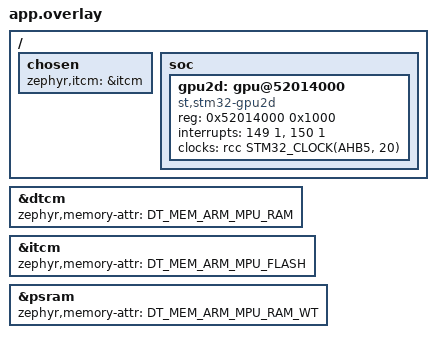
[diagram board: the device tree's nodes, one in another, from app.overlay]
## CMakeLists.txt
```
# SPDX-License-Identifier: Apache-2.0
#
# PSX GPU for the STM32H7S78-DK: the emulator on the i.MX RT1050 sends its GPU
# commands over Ethernet, this board rasterizes them (PSXE/dev/gpu.c, the same
# file the RT1050 build uses) and shows the picture.

cmake_minimum_required(VERSION 3.20.0)

find_package(Zephyr REQUIRED HINTS $ENV{ZEPHYR_BASE})
project(h7s7_psxgpu LANGUAGES C)

set(PSXE_ROOT "${CMAKE_CURRENT_SOURCE_DIR}/..")
set(NEOCHROM_ROOT "${CMAKE_CURRENT_SOURCE_DIR}/../h7s7_neochrom")

# -----------------------------------------------------------------------------
# NemaGFX - the NeoChrom driver library (see h7s7_neochrom/CMakeLists.txt)
# -----------------------------------------------------------------------------
set(NEMAGFX_ROOT "$ENV{NEMAGFX_ROOT}" CACHE PATH "NemaGFX package root")
if(NOT NEMAGFX_ROOT)
  if(DEFINED ZEPHYR_LVGL_MODULE_DIR AND EXISTS "${ZEPHYR_LVGL_MODULE_DIR}/libs/nema_gfx")
    set(NEMAGFX_ROOT "${ZEPHYR_LVGL_MODULE_DIR}/libs/nema_gfx")
  else()
    message(FATAL_ERROR "NemaGFX not found: run 'west update' (lvgl module) or pass -DNEMAGFX_ROOT=<dir>")
  endif()
endif()

if(EXISTS "${NEMAGFX_ROOT}/include/cortex_m55_m7/nema_core.h")
  set(NEMAGFX_INC "${NEMAGFX_ROOT}/include/cortex_m55_m7")
else()
  set(NEMAGFX_INC "${NEMAGFX_ROOT}/include")
endif()

if(CONFIG_FP_HARDABI)
  set(NEMAGFX_LIB "${NEMAGFX_ROOT}/lib/core/cortex_m7/gcc/libnemagfx-float-abi-hard.a")
else()
  set(NEMAGFX_LIB "${NEMAGFX_ROOT}/lib/core/cortex_m7/gcc/libnemagfx.a")
endif()

if(NOT EXISTS "${NEMAGFX_INC}/nema_core.h" OR NOT EXISTS "${NEMAGFX_LIB}")
  message(FATAL_ERROR "Incomplete NemaGFX package in ${NEMAGFX_ROOT}")
endif()
message(STATUS "NemaGFX: ${NEMAGFX_LIB}")

add_library(nemagfx STATIC IMPORTED GLOBAL)
set_target_properties(nemagfx PROPERTIES IMPORTED_LOCATION "${NEMAGFX_LIB}")

# the HAL Ethernet driver's descriptor rings (the same value for the HAL and for us)
zephyr_compile_definitions(ETH_RX_DESC_CNT=64 ETH_TX_DESC_CNT=4)

target_include_directories(app PRIVATE
  src
  src/shim
  "${PSXE_ROOT}/PSXE"
  "${PSXE_ROOT}/PSXE/dev"
  "${PSXE_ROOT}/PSXE/link"
  "${NEOCHROM_ROOT}/src"
  "${NEMAGFX_INC}"
)
target_link_libraries(app PUBLIC nemagfx)

# gpu.h is read by every file here: on its own, without the emulator's ic.h/cpu.h
target_compile_definitions(app PRIVATE PSX_GPU_STANDALONE=1 PSXE_GPU_REMOTE=0 PSX_PROFILE=1)

target_sources(app PRIVATE
  src/main.c
  src/eth_raw.c
  src/present.c
  src/nema_raster.c
  src/shim/psx_shim.c
  "${NEOCHROM_ROOT}/src/nema_hal_zephyr.c"
  "${NEOCHROM_ROOT}/src/font8x8.c"
  "${PSXE_ROOT}/PSXE/dev/gpu.c"
)

# the rasterizer: built as on the RT1050 (-O3, unrolled), on its own
set_source_files_properties("${PSXE_ROOT}/PSXE/dev/gpu.c" PROPERTIES
  COMPILE_OPTIONS "-O3;-funroll-loops;-Wno-unused-function;-Wno-unused-variable;-Wno-sign-compare;-Wno-missing-braces")
```

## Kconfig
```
# SPDX-License-Identifier: Apache-2.0

mainmenu "PSX GPU board"

menu "PSX GPU board"

config PSXGPU_ETH
	bool "Raw Ethernet through the STM32 HAL"
	default y
	select USE_STM32_HAL_ETH
	select NOCACHE_MEMORY
	help
	  The link to the CPU board: raw Ethernet frames through the HAL ETH
	  driver, without the Zephyr network stack (src/eth_raw.c).

# the NemaGFX platform layer shared with the showcase (h7s7_neochrom/src/nema_hal_zephyr.c)
config NEOCHROM_NEMA_POOL_SIZE
	int "NemaGFX graphics memory pool in non-cacheable SRAM [bytes]"
	default 16384
	help
	  The NemaGFX allocator's pool: its ring buffer and little else here.
	  Non-cacheable, so the GPU always sees what the CPU wrote.

config NEOCHROM_GPU2D_ICACHE
	bool "Enable the GPU2D read cache"
	default y
	help
	  The GPU2D's own read cache. Not coherent: the presenter asks for an
	  invalidation (ext-hold) before the GPU reads what the CPU repacked.

endmenu

source "Kconfig.zephyr"
```

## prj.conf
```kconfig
# Display: LTDC, frame buffers owned by the application (zero-copy flip)
CONFIG_DISPLAY=y
CONFIG_STM32_LTDC_RGB565=y
CONFIG_STM32_LTDC_FB_NUM=0
CONFIG_MEMC=y
CONFIG_GPIO=y

# Ethernet: the HAL driver alone, no network stack (see src/eth_raw.c)
CONFIG_NETWORKING=n
CONFIG_PINCTRL=y

# Floating point: NemaGFX is linked in its hard-float flavour
CONFIG_FPU=y
CONFIG_FPU_SHARING=y
CONFIG_FP_HARDABI=y

# CPU <-> GPU / DMA coherency
CONFIG_CACHE_MANAGEMENT=y
CONFIG_NOCACHE_MEMORY=y

# Memory / threads
CONFIG_HEAP_MEM_POOL_SIZE=16384
CONFIG_MAIN_STACK_SIZE=16384
CONFIG_ISR_STACK_SIZE=4096
CONFIG_MAIN_THREAD_PRIORITY=5

# Speed
CONFIG_SPEED_OPTIMIZATIONS=y

# Diagnostics
CONFIG_PRINTK=y
CONFIG_LOG=y
CONFIG_LOG_DEFAULT_LEVEL=3
CONFIG_LOG_BUFFER_SIZE=4096

# Keep the debug port alive while the idle thread sleeps (hot attach, SWD memory dumps)
CONFIG_STM32_ENABLE_DEBUG_SLEEP_STOP=y
```

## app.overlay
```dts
/*
 * NeoChrom GPU2D (Think Silicon NEMA|P): not in the SoC devicetree yet, so the
 * application adds it (as h7s7_neochrom does). RM0477 / stm32h7s7xx.h:
 *   GPU2D_BASE = 0x52014000, IRQs 149 (gpu2d) and 150 (gpu2d_er),
 *   clock: RCC_AHB5ENR bit 20
 */

/ {
	chosen {
		zephyr,itcm = &itcm;
	};

	soc {
		gpu2d: gpu@52014000 {
			compatible = "st,stm32-gpu2d";
			reg = <0x52014000 0x1000>;
			interrupts = <149 1>, <150 1>;
			interrupt-names = "gpu2d", "gpu2d_er";
			clocks = <&rcc STM32_CLOCK(AHB5, 20)>;
			status = "okay";
		};
	};
};

/* an MPU region for the DTCM: the GPU state lives there (psx_gpu_platform.h) */
&dtcm {
	zephyr,memory-attr = <DT_MEM_ARM_MPU_RAM>;
};

/* the innermost rasterizer runs from the ITCM: an executable MPU region (Zephyr's RAM
   attribute is execute-never in an XIP image; the flash one is read-only and executable,
   and the code is copied in at boot, before the MPU is set up) */
&itcm {
	zephyr,memory-attr = <DT_MEM_ARM_MPU_FLASH>;
};

/* the PSRAM (VRAM, frame buffers) write-through: a span written by the rasterizer
   neither fills a cache line first (a 189 cycle read of what it overwrites) nor
   evicts the texture lines it needs next; the write buffer merges the stores */
&psram {
	zephyr,memory-attr = <DT_MEM_ARM_MPU_RAM_WT>;
};
```

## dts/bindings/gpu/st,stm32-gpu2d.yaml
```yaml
# SPDX-License-Identifier: Apache-2.0

description: |
  STM32 NeoChrom graphics accelerator (GPU2D, Think Silicon NEMA|P core).
  The first interrupt signals command-list completion, the second one is the
  "error" line that on AXI-attached instances also carries the GPU cache
  maintenance (external hold) handshakes.

compatible: "st,stm32-gpu2d"

include: base.yaml

properties:
  reg:
    required: true

  interrupts:
    required: true

  interrupt-names:
    required: true

  clocks:
    required: true
```

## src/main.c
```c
/*
 * PSX GPU on the STM32H7S78-DK.
 *
 * The emulator on the i.MX RT1050 sends its GPU commands over Ethernet (see
 * PSXE/link/psxe_link.h); this board keeps the VRAM, rasterizes with the very
 * same gpu.c and shows the picture on its panel.
 *
 *   receive thread   Ethernet frames -> the receive ring (link_ring.h)
 *   main thread      ring -> records -> gpu.c; vertical blank -> present;
 *                    STATUS frames back (flow control), statistics on the UART
 */

#include <string.h>

#include <zephyr/kernel.h>
#include <zephyr/cache.h>
#include <zephyr/device.h>
#include <zephyr/drivers/gpio.h>
#include <zephyr/linker/devicetree_regions.h>
#include <zephyr/sys/printk.h>
#include <zephyr/logging/log.h>

#include "eth_raw.h"
#include "gpu.h"
#include "psx_gpu_platform.h"
#include "link_ring.h"
#include "nema_port.h"
#include "nema_raster.h"
#include "present.h"
#include "psxe_link.h"

LOG_MODULE_REGISTER(main, LOG_LEVEL_INF);

static const uint8_t mac_gpu[6] = PSXE_LINK_MAC_GPU;
static const uint8_t mac_cpu[6] = PSXE_LINK_MAC_CPU;

static uint8_t ring_mem[PSXE_LINK_RING_BYTES]
	__attribute__((section(LINKER_DT_NODE_REGION_NAME(DT_NODELABEL(psram))))) __aligned(64);
static struct link_ring ring;
static K_SEM_DEFINE(ring_sem, 0, 1);

static psx_gpu_t *gpu;

/* link state */
static uint32_t consumed;         /* payload bytes of frames fully processed     */
static uint32_t consumed_told;    /* ... as of the last STATUS                    */
static int64_t status_at;         /* when the last STATUS went out                */
static uint16_t rx_seq;
static bool rx_seq_known;
static bool resync;               /* frames were lost: wait for a command boundary */
static uint32_t errors;
static uint32_t lost_frames, resyncs, ring_full, bad_frames;
static uint32_t dropped_bytes; /* frames the ring had no room for: never stored, so consumed at once */
static uint32_t boot_id;
static uint32_t frames_in, words_gp0, gp1_words, vblanks;
static uint32_t pictures;         /* finished pictures from the CPU board (the hybrid) */
static uint32_t busy_cyc;         /* cycles spent processing frames since the last report */
static int64_t last_frame_at;

#if DT_NODE_EXISTS(DT_ALIAS(led0))
static const struct gpio_dt_spec led = GPIO_DT_SPEC_GET(DT_ALIAS(led0), gpios);
#endif

/* ---- receive thread ---------------------------------------------------------- */

static void rx_sink(const uint8_t *frame, size_t len)
{
	if (len < PSXE_LINK_ETH_HDR + PSXE_LINK_HDR) {
		return;
	}
	if (frame[12] != (PSXE_LINK_ETHERTYPE >> 8) || frame[13] != (PSXE_LINK_ETHERTYPE & 0xffu)) {
		return; /* not ours */
	}
	if (!link_ring_put(&ring, frame + PSXE_LINK_ETH_HDR, (uint32_t)(len - PSXE_LINK_ETH_HDR))) {
		ring_full++;
		errors++;
		dropped_bytes += (uint32_t)(len - PSXE_LINK_ETH_HDR);
		return;
	}
	k_sem_give(&ring_sem);
}

static void rx_thread(void *a, void *b, void *c)
{
	ARG_UNUSED(a);
	ARG_UNUSED(b);
	ARG_UNUSED(c);
	while (1) {
		(void)eth_raw_receive(rx_sink, K_MSEC(100));
	}
}

K_THREAD_DEFINE(rx_tid, 4096, rx_thread, NULL, NULL, NULL, K_PRIO_PREEMPT(1), 0, 0);

/* ---- sending ---------------------------------------------------------------- */

/* the payload 4 byte aligned: the Ethernet header is 14 bytes */
static uint8_t tx_frame_mem[2 + PSXE_LINK_FRAME_MAX] __aligned(4);
#define tx_frame (tx_frame_mem + 2)
static uint16_t tx_seq;

static uint32_t *tx_begin(void)
{
	memcpy(tx_frame, mac_cpu, 6);
	memcpy(tx_frame + 6, mac_gpu, 6);
	tx_frame[12] = PSXE_LINK_ETHERTYPE >> 8;
	tx_frame[13] = PSXE_LINK_ETHERTYPE & 0xffu;
	tx_frame[14] = PSXE_LINK_VERSION;
	tx_frame[15] = 0;
	tx_frame[16] = (uint8_t)tx_seq;
	tx_frame[17] = (uint8_t)(tx_seq >> 8);
	tx_seq++;
	return (uint32_t *)(tx_frame + PSXE_LINK_ETH_HDR + PSXE_LINK_HDR);
}

static void tx_end(uint32_t *end)
{
	size_t len = (size_t)((uint8_t *)end - tx_frame);

	if (len < 60) {
		memset(tx_frame + len, 0, 60 - len);
		len = 60;
	}
	(void)eth_raw_send(tx_frame, len);
}

static void send_status(void)
{
	struct present_stats ps;
	uint32_t *w = tx_begin();

	present_get_stats(&ps);
	w[0] = PSXE_REC_HDR(PSXE_REC_STATUS, 0, PSXE_STATUS_WORDS);
	w[1 + PSXE_STATUS_CONSUMED] = consumed + dropped_bytes;
	w[1 + PSXE_STATUS_FLAGS] = PSXE_STATUS_FLAG_READY | (resync ? PSXE_STATUS_FLAG_RESYNC : 0u);
	w[1 + PSXE_STATUS_RING] = PSXE_LINK_RING_BYTES;
	w[1 + PSXE_STATUS_PRESENTED] = ps.frames;
	w[1 + PSXE_STATUS_ERRORS] = errors;
	w[1 + PSXE_STATUS_BOOT] = boot_id;
	w[1 + PSXE_STATUS_BUSY] = 0; /* not measured here: sent as zero rather than as whatever the buffer held */
	tx_end(w + 1 + PSXE_STATUS_WORDS);
	consumed_told = consumed;
	status_at = k_uptime_get();
}

/* the words a VRAM -> CPU transfer returns, as GPUREAD would give them */
static void send_vram_read(void)
{
	while (gpu->c0_tsiz > 0) {
		uint32_t n = (uint32_t)(gpu->c0_tsiz + 1) / 2u;

		if (n > PSXE_LINK_PAYLOAD_WORDS - 1u) {
			n = PSXE_LINK_PAYLOAD_WORDS - 1u;
		}
		uint32_t *w = tx_begin();

		w[0] = PSXE_REC_HDR(PSXE_REC_VRAM, 0, n);
		for (uint32_t i = 0; i < n; i++) {
			w[1 + i] = psx_gpu_read32(gpu, 0);
		}
		tx_end(w + 1 + n);
	}
}

/* ---- the command stream ------------------------------------------------------- */

static void gpu_reset(void)
{
	psx_gpu_init(gpu, NULL);
	resync = false;
	LOG_INF("GPU reset by the CPU board");
}

static void feed_gp0(const uint32_t *w, uint32_t n)
{
	while (n) {
		if (gpu->state == GPU_STATE_RECV_DATA) {
			/* whole rows of an upload straight into VRAM */
			uint32_t done = psx_gpu_write_bulk(gpu, w, n);

			if (done) {
				w += done;
				n -= done;
				continue;
			}
		}
		psx_gpu_write32(gpu, 0, *w++);
		n--;
		if (gpu->c0_tsiz > 0) {
			send_vram_read();
		}
	}
}

/* the last few megabytes of what came over the link, for a debugger to read:
   g_cap_pos is where the next frame goes; each frame is its length in bytes
   (one word, then the payload padded to words), capturing stops when it is full */
#define CAP_BYTES (8u * 1024u * 1024u)
uint8_t g_cap[CAP_BYTES] __attribute__((section(LINKER_DT_NODE_REGION_NAME(DT_NODELABEL(psram))))) __aligned(64);
volatile uint32_t g_cap_pos;
volatile uint32_t g_cap_wraps;
volatile uint32_t g_cap_on = 1;

/* a debugger writes a capture into g_cap and sets this to 1: the stream is fed
   from there instead of the link, up to g_replay_vblanks vertical blanks (0 =
   all of it), and then everything stops at 2 so that VRAM can be read */
volatile uint32_t g_replay;
volatile uint32_t g_replay_vblanks;

static void capture(const uint8_t *p, uint32_t len)
{
	const uint32_t need = 4u + ((len + 3u) & ~3u);

	if (!g_cap_on) {
		return;
	}
	if (g_cap_pos + need + 4u > CAP_BYTES) {
		*(uint32_t *)&g_cap[g_cap_pos] = 0xffffffffu; /* the end marker */
		g_cap_on = 0; /* the first CAP_BYTES since boot: the VRAM restore, then the stream */
		g_cap_wraps++;
		return;
	}
	*(uint32_t *)&g_cap[g_cap_pos] = len;
	memcpy(&g_cap[g_cap_pos + 4u], p, len);
	g_cap_pos += need;
}

static void process_frame(const uint8_t *p, uint32_t len)
{
	if (!g_replay) {
		capture(p, len);
	}
	if (PSXE_LINK_HDR_VERSION(p) != PSXE_LINK_VERSION) {
		bad_frames++;
		errors++;
		return;
	}
	uint16_t seq = PSXE_LINK_HDR_SEQ(p);

	if (rx_seq_known && seq != rx_seq) {
		lost_frames += (uint16_t)(seq - rx_seq);
		errors++;
		resync = true;
	}
	rx_seq = (uint16_t)(seq + 1);
	rx_seq_known = true;
	frames_in++;

	const uint32_t *w = (const uint32_t *)(p + PSXE_LINK_HDR);
	uint32_t words = (len - PSXE_LINK_HDR) / 4u;

	while (words >= 1u) {
		const uint32_t h = *w++;
		const uint32_t n = PSXE_REC_LEN(h);

		words--;
		if (n > words) {
			bad_frames++;
			errors++;
			break;
		}
		switch (PSXE_REC_TYPE(h)) {
		case PSXE_REC_GP0:
			if (resync) {
				if (!(PSXE_REC_FLAGS(h) & PSXE_REC_GP0_BOUNDARY)) {
					break; /* mid-command: wait for a boundary */
				}
				gpu->state = GPU_STATE_RECV_CMD;
				resync = false;
				resyncs++;
			}
			feed_gp0(w, n);
			words_gp0 += n;
			break;
		case PSXE_REC_GP1:
			if (n >= 1u) {
				psx_gpu_write32(gpu, 4, w[0]);
				gp1_words++;
			}
			break;
		case PSXE_REC_FRAME:
			if (n >= PSXE_FRAME_WORDS) {
				const uint32_t pw = w[0] & 0xffffu;
				const uint32_t ph = w[0] >> 16;
				const uint32_t row = w[1] & 0xffffu;
				const uint32_t rows = w[1] >> 16;
				const uint32_t flags = w[2];
				const uint32_t mode = w[3];
				const uint32_t row_bytes = (flags & PSXE_FRAME_24BPP) ? (pw * 3u) : (pw * 2u);
				const uint32_t row_words = (row_bytes + 3u) >> 2;
				const uint32_t *px = w + PSXE_FRAME_WORDS;

				if (pw && (pw <= PSX_GPU_FB_WIDTH) && ((row + rows) <= PSX_GPU_FB_HEIGHT) &&
				    (PSXE_FRAME_WORDS + rows * row_words <= n)) {
					/* a whole picture makes good whatever a lost frame spoiled */
					if (flags & PSXE_FRAME_WHOLE) {
						resync = false;
					}
					present_rows(px, pw, row, rows, row_words * 4u, flags);

					if (flags & PSXE_FRAME_LAST) {
						present_show(pw, ph, flags, mode);
						pictures++;
					}
				} else {
					bad_frames++;
					errors++;
				}
			}
			break;

		case PSXE_REC_VBLANK:
			if (n >= 1u) {
				psx_gpu_set_field(gpu, PSXE_VBLANK_FIELD(w[0]));
				vblanks++;
				present_vblank(gpu);
			}
			break;
		case PSXE_REC_RESET:
			gpu_reset();
			break;
		default:
			break;
		}
		w += n;
		words -= n;
	}
	consumed += len;
}

static void replay(void)
{
	uint32_t pos = 0;
	const uint32_t vb0 = vblanks;

	g_cap_on = 0;
	rx_seq_known = false;
	LOG_INF("replaying the capture");
	while (pos + 4u <= CAP_BYTES) {
		const uint32_t len = *(const uint32_t *)&g_cap[pos];

		if ((len == 0xffffffffu) || (len == 0u) || (len > PSXE_LINK_FRAME_MAX)) {
			break;
		}
		process_frame(&g_cap[pos + 4u], len);
		pos += 4u + ((len + 3u) & ~3u);
		if (g_replay_vblanks && ((vblanks - vb0) >= g_replay_vblanks)) {
			break;
		}
	}
	psx_raster_sync();
	sys_cache_data_invd_range(gpu->vram, PSX_GPU_VRAM_SIZE);
	LOG_INF("replay done: %u bytes, %u vblanks", pos, vblanks - vb0);
	g_replay = 2;
	while (g_replay == 2) {
		k_msleep(10);
	}
}

/* ---- main --------------------------------------------------------------------- */

int main(void)
{
	printk("\n*** PSX GPU board - %s ***\n", CONFIG_BOARD_TARGET);

#if DT_NODE_EXISTS(DT_ALIAS(led0))
	if (gpio_is_ready_dt(&led)) {
		gpio_pin_configure_dt(&led, GPIO_OUTPUT_INACTIVE);
	}
#endif

	link_ring_init(&ring, ring_mem, sizeof(ring_mem));
	boot_id = k_cycle_get_32() | 1u;

	if (present_init() != 0) {
		LOG_ERR("display init failed");
		return 0;
	}
	psxgpu_prof_init();
	gpu = psx_gpu_create();
	psx_gpu_init(gpu, NULL);
	psxgpu_mem_bench();
	present_bench(gpu);
	psx_raster_selftest(gpu);
	psx_raster_tritest(gpu);
	if (gpu->vram == NULL) {
		LOG_ERR("no VRAM");
		return 0;
	}
	present_text("PSX GPU", "waiting for the CPU board (Ethernet)");

	if (eth_raw_init(mac_gpu) != 0) {
		present_text("PSX GPU", "Ethernet init failed");
		return 0;
	}

	int64_t t_log = k_uptime_get();
	int64_t t_link = 0;
	bool shown_waiting = true;
	bool was_up = false;

	while (1) {
		int64_t now = k_uptime_get();

		/* the PHY, every 200 ms */
		if (now - t_link >= 200) {
			t_link = now;
			bool up = eth_raw_link_poll();

			if (up != was_up) {
				was_up = up;
				if (up) {
					send_status();
				}
			}
		}

		if (g_replay == 1) {
			replay();
		}

		/* everything the ring holds */
		uint32_t len;
		const uint8_t *p;
		int n = 0;

		while ((p = link_ring_peek(&ring, &len)) != NULL) {
			const uint32_t t0 = k_cycle_get_32();

			process_frame(p, len);
			busy_cyc += k_cycle_get_32() - t0;
			link_ring_drop(&ring, len);
			last_frame_at = now;
			shown_waiting = false;
			if (++n >= 64) {
				break; /* let the status go out */
			}
		}

		/* flow control: what was consumed, promptly; and a heartbeat */
		if (eth_raw_link_up()) {
			if ((consumed - consumed_told) >= 16u * 1024u ||
			    ((consumed != consumed_told) && (now - status_at >= 2)) ||
			    (now - status_at >= 250)) {
				send_status();
			}
		}

		if (n == 0) {
			(void)k_sem_take(&ring_sem, K_MSEC(2));
		}

		now = k_uptime_get();
		if (!shown_waiting && now - last_frame_at > 3000) {
			present_text("PSX GPU", eth_raw_link_up() ? "no commands from the CPU board"
							       : "no Ethernet link");
			shown_waiting = true;
		}

		if (now - t_log >= 5000) {
			struct eth_raw_stats es;
			struct present_stats ps;
			struct nema_port_stats ns;
			struct psx_raster_stats rs;

			const uint32_t window_ms = (uint32_t)(now - t_log);
			const uint32_t busy_ms = k_cyc_to_ms_floor32(busy_cyc);

			t_log = now;
			eth_raw_get_stats(&es);
			present_get_stats(&ps);
			nema_port_get_stats(&ns);
			psx_raster_get_stats(&rs);
			printk("link %s: rx %u frames %u KB (drop %u nodesc %u) tx %u (err %u) irq %u | "
			       "gp0 %u words, gp1 %u, vblank %u, lost %u, resync %u, ring full %u, "
			       "bad %u, ring %u/%u KB | pictures %u presented %u (skipped %u) %ux%u mode %03x "
			       "repack %u us gpu %u us | busy %u%% (present %u%%) | gpu2d irq %u err %u timeouts %u\n",
			       eth_raw_link_up() ? "up" : "down", es.rx_frames, es.rx_bytes / 1024u,
			       es.rx_dropped, es.rx_no_desc, es.tx_frames, es.tx_errors, es.irqs, words_gp0, gp1_words,
			       vblanks, lost_frames, resyncs, ring_full, bad_frames,
			       ring.high_water / 1024u, ring.size / 1024u, pictures, ps.frames, ps.skipped,
			       ps.src_w, ps.src_h, ps.mode, ps.repack_us, ps.gpu_us,
			       (busy_ms * 100u) / (window_ms ? window_ms : 1u),
			       (ps.cpu_us_acc / 10u) / (window_ms ? window_ms : 1u), ns.cl_irqs, ns.err_irqs,
			       ns.timeouts);
			printk("raster: %u prims (%u flat, %u gouraud, %u textured, %u rects, %u lines) | "
			       "%u binds (%u 15bpp), %u palettes | %u flushes | cpu %u ms (bind %u ms), gpu %u ms, %u hangs\n",
			       rs.prims, rs.flat, rs.gouraud, rs.textured, rs.rects, rs.lines, rs.tex_binds,
			       rs.tex15, rs.palettes, rs.flushes, k_cyc_to_ms_floor32(rs.cpu_cyc),
			       k_cyc_to_ms_floor32(rs.bind_cyc), k_cyc_to_ms_floor32(rs.gpu_cyc), rs.hangs);
			psx_raster_reset_stats();
			ring.high_water = 0;
			busy_cyc = 0;
			present_stats_reset();
			psxgpu_prof_report();
#if DT_NODE_EXISTS(DT_ALIAS(led0))
			if (gpio_is_ready_dt(&led)) {
				gpio_pin_toggle_dt(&led);
			}
#endif
		}
	}
	return 0;
}
```

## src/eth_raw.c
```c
/*
 * Raw Ethernet through the STM32 HAL ETH driver (the same HAL the Zephyr
 * Ethernet driver uses underneath), on the LAN8742 PHY of the STM32H7S78-DK.
 *
 * Receive: the HAL hands the DMA a buffer through HAL_ETH_RxAllocateCallback
 * and links what it filled through HAL_ETH_RxLinkCallback; HAL_ETH_ReadData
 * returns the chain of one frame. A frame fits one buffer (the buffers are
 * larger than a frame), so a chain is one buffer long here.
 * Transmit: one frame at a time, waited for - the GPU board sends little.
 *
 * Descriptors and buffers are in non-cacheable SRAM (CONFIG_NOCACHE_MEMORY),
 * so no cache maintenance is needed on either side.
 */

#include <stdio.h>
#include <string.h>

#include <zephyr/kernel.h>
#include <zephyr/device.h>
#include <zephyr/devicetree.h>
#include <zephyr/irq.h>
#include <zephyr/drivers/clock_control.h>
#include <zephyr/drivers/clock_control/stm32_clock_control.h>
#include <zephyr/drivers/pinctrl.h>
#include <zephyr/linker/section_tags.h>
#include <zephyr/linker/devicetree_regions.h>
#include <zephyr/cache.h>
#include <zephyr/logging/log.h>
#include <soc.h>

#include <stm32h7rsxx_hal.h>

#include "eth_raw.h"

LOG_MODULE_REGISTER(eth_raw, LOG_LEVEL_INF);

#define ETH_NODE DT_NODELABEL(mac)
#define MDIO_NODE DT_NODELABEL(mdio)
BUILD_ASSERT(DT_NODE_HAS_STATUS_OKAY(ETH_NODE), "the board's Ethernet node is off");
BUILD_ASSERT(DT_NODE_HAS_STATUS_OKAY(MDIO_NODE), "the board's MDIO node is off");

/* the RMII pins are the MAC's; MDC (PC1, behind JP6) and MDIO (PA2) are the MDIO node's */
PINCTRL_DT_DEFINE(ETH_NODE);
PINCTRL_DT_DEFINE(MDIO_NODE);

#define PHY_ADDR 0U  /* LAN8742A on the DK: address 0 (see the board devicetree) */

/* IEEE 802.3 registers, and the LAN8742's speed/duplex status */
#define PHY_BMCR 0U
#define PHY_BMSR 1U
#define PHY_SCSR 31U
#define PHY_BMCR_RESET BIT(15)
#define PHY_BMCR_AUTONEG BIT(12)
#define PHY_BMCR_RESTART_AN BIT(9)
#define PHY_BMSR_AN_DONE BIT(5)
#define PHY_BMSR_LINK BIT(2)
#define PHY_SCSR_SPEED_MASK (7U << 2)
#define PHY_SCSR_100M BIT(3)
#define PHY_SCSR_FULL BIT(4)

#define RX_BUF_SIZE 1536U  /* > 1514 + CRC, a multiple of 32 */
#define RX_BUFS (ETH_RX_DESC_CNT * 2)
#define TX_BUF_SIZE 1536U

static ETH_HandleTypeDef heth;
static ETH_DMADescTypeDef rx_desc[ETH_RX_DESC_CNT] __nocache __aligned(32);
static ETH_DMADescTypeDef tx_desc[ETH_TX_DESC_CNT] __nocache __aligned(32);
/* the receive buffers are in the PSRAM (there are many, so that a burst at line
   rate never runs the DMA out of them); the CPU only ever reads them, after an
   invalidate, so the cache never holds anything the DMA could be overwritten by */
static uint8_t rx_buf[RX_BUFS][RX_BUF_SIZE] __attribute__((section(LINKER_DT_NODE_REGION_NAME(DT_NODELABEL(psram)))))
	__aligned(32);
static uint8_t tx_buf[TX_BUF_SIZE] __nocache __aligned(32);
static uint32_t rx_no_desc; /* the DMA had no descriptor for a frame (receive buffer unavailable) */

/* what the HAL chains: one per receive buffer */
struct rx_chunk {
	struct rx_chunk *next;
	uint16_t len;
	bool used;
};

static struct rx_chunk rx_chunk[RX_BUFS];
static uint8_t mac_addr[6];
static bool link_up;
static bool started;
static K_SEM_DEFINE(rx_sem, 0, 1);
static K_SEM_DEFINE(tx_sem, 0, 1);
static K_MUTEX_DEFINE(tx_mtx);
static struct eth_raw_stats stats;

/* ---- HAL callbacks ------------------------------------------------------- */

void HAL_ETH_RxAllocateCallback(uint8_t **buff)
{
	for (int i = 0; i < RX_BUFS; i++) {
		if (!rx_chunk[i].used) {
			rx_chunk[i].used = true;
			rx_chunk[i].next = NULL;
			rx_chunk[i].len = 0;
			*buff = rx_buf[i];
			return;
		}
	}
	stats.rx_dropped++;
	*buff = NULL;
}

void HAL_ETH_RxLinkCallback(void **pStart, void **pEnd, uint8_t *buff, uint16_t Length)
{
	int i = (int)((buff - &rx_buf[0][0]) / RX_BUF_SIZE);
	struct rx_chunk *c = &rx_chunk[i];

	c->len = Length;
	c->next = NULL;
	if (*pStart == NULL) {
		*pStart = c;
	} else {
		((struct rx_chunk *)*pEnd)->next = c;
	}
	*pEnd = c;
}

void HAL_ETH_TxFreeCallback(uint32_t *buff)
{
	ARG_UNUSED(buff);
}

void HAL_ETH_RxCpltCallback(ETH_HandleTypeDef *h)
{
	ARG_UNUSED(h);
	k_sem_give(&rx_sem);
}

void HAL_ETH_TxCpltCallback(ETH_HandleTypeDef *h)
{
	ARG_UNUSED(h);
	k_sem_give(&tx_sem);
}

void HAL_ETH_ErrorCallback(ETH_HandleTypeDef *h)
{
	if ((HAL_ETH_GetDMAError(h) & ETH_DMA_RX_BUFFER_UNAVAILABLE_FLAG) != 0U) {
		rx_no_desc++;
	}
	stats.tx_errors++;
	/* a receive buffer shortage stops the DMA: it goes on once buffers are back */
	k_sem_give(&rx_sem);
}

static void eth_isr(const void *arg)
{
	ARG_UNUSED(arg);
	stats.irqs++;
	HAL_ETH_IRQHandler(&heth);
}

/* ---- PHY ------------------------------------------------------------------ */

static int phy_read(uint32_t reg, uint32_t *val)
{
	return HAL_ETH_ReadPHYRegister(&heth, PHY_ADDR, reg, val) == HAL_OK ? 0 : -EIO;
}

static int phy_write(uint32_t reg, uint32_t val)
{
	return HAL_ETH_WritePHYRegister(&heth, PHY_ADDR, reg, val) == HAL_OK ? 0 : -EIO;
}

/* the PHY's registers on the console: identity, negotiation, the LAN8742's speed word */
static void phy_dump(const char *when)
{
	static const uint32_t regs[] = {0, 1, 2, 3, 4, 5, 17, 18, 27, 31};
	char line[160];
	size_t n = 0;

	for (size_t i = 0; i < ARRAY_SIZE(regs); i++) {
		uint32_t v = 0;

		if (phy_read(regs[i], &v)) {
			n += snprintf(line + n, sizeof(line) - n, " r%u=????", (unsigned)regs[i]);
		} else {
			n += snprintf(line + n, sizeof(line) - n, " r%u=%04x", (unsigned)regs[i], (unsigned)v);
		}
		if (n >= sizeof(line) - 12) {
			break;
		}
	}
	LOG_INF("PHY %s:%s", when, line);
}

static int phy_init(void)
{
	uint32_t v;

	if (phy_write(PHY_BMCR, PHY_BMCR_RESET)) {
		return -EIO;
	}
	for (int i = 0; i < 100; i++) {
		k_msleep(5);
		if (phy_read(PHY_BMCR, &v) == 0 && (v & PHY_BMCR_RESET) == 0U) {
			break;
		}
	}
	if (phy_read(PHY_BMCR, &v) || (v & PHY_BMCR_RESET)) {
		LOG_ERR("PHY does not answer (BMCR %08x) - is JP6 in the PC1 position?", v);
		phy_dump("dead");
		return -EIO;
	}
	int ret = phy_write(PHY_BMCR, PHY_BMCR_AUTONEG | PHY_BMCR_RESTART_AN);

	phy_dump("after init");
	return ret;
}

/* the link came up: the MAC takes the negotiated speed and duplex, and runs */
static int mac_start(void)
{
	ETH_MACConfigTypeDef mac;
	uint32_t scsr = 0;

	(void)phy_read(PHY_SCSR, &scsr);
	if (HAL_ETH_GetMACConfig(&heth, &mac) != HAL_OK) {
		return -EIO;
	}
	mac.Speed = (scsr & PHY_SCSR_100M) ? ETH_SPEED_100M : ETH_SPEED_10M;
	mac.DuplexMode = (scsr & PHY_SCSR_FULL) ? ETH_FULLDUPLEX_MODE : ETH_HALFDUPLEX_MODE;
	if (HAL_ETH_SetMACConfig(&heth, &mac) != HAL_OK) {
		return -EIO;
	}
	if (HAL_ETH_Start_IT(&heth) != HAL_OK) {
		LOG_ERR("HAL_ETH_Start_IT failed");
		return -EIO;
	}
	started = true;
	LOG_INF("link up: %s %s duplex", (scsr & PHY_SCSR_100M) ? "100 Mbit" : "10 Mbit",
		(scsr & PHY_SCSR_FULL) ? "full" : "half");
	return 0;
}

static void mac_stop(void)
{
	if (started) {
		(void)HAL_ETH_Stop_IT(&heth);
		started = false;
	}
	LOG_INF("link down");
}

bool eth_raw_link_poll(void)
{
	uint32_t bmsr = 0;
	static uint32_t polls;

	if (phy_read(PHY_BMSR, &bmsr)) {
		if ((++polls % 50) == 0) {
			LOG_WRN("PHY MDIO read fails - is JP6 in the PC1 position?");
		}
		return link_up;
	}
	if (!(bmsr & PHY_BMSR_LINK) && ((++polls % 50) == 0)) {
		phy_dump("no link");
	}
	/* the link bit latches low: read twice to see the current state. A low
	   first read while the link is up here means it went down and came back
	   between two polls - renegotiated, possibly to another duplex (a partner
	   that was not negotiating yet gives half duplex): the MAC has to take the
	   new result, or every frame collides with a full duplex partner */
	bool flapped = false;

	if ((bmsr & PHY_BMSR_LINK) == 0U) {
		flapped = link_up;
		(void)phy_read(PHY_BMSR, &bmsr);
	}
	bool up = (bmsr & PHY_BMSR_LINK) != 0U && (bmsr & PHY_BMSR_AN_DONE) != 0U;

	if (up && link_up && flapped) {
		mac_stop();
		link_up = false;
	}
	if (up && !link_up) {
		if (mac_start() == 0) {
			link_up = true;
		}
	} else if (!up && link_up) {
		mac_stop();
		link_up = false;
	}
	return link_up;
}

bool eth_raw_link_up(void)
{
	return link_up;
}

/* ---- init ----------------------------------------------------------------- */

int eth_raw_init(const uint8_t mac[6])
{
	static const struct stm32_pclken pclken[] = STM32_DT_CLOCKS(ETH_NODE);
	const struct device *clk = DEVICE_DT_GET(STM32_CLOCK_CONTROL_NODE);
	int ret;

	memcpy(mac_addr, mac, 6);

	if (!device_is_ready(clk)) {
		return -ENODEV;
	}
	for (size_t i = 0; i < ARRAY_SIZE(pclken); i++) {
		ret = clock_control_on(clk, (clock_control_subsys_t)&pclken[i]);
		if (ret) {
			LOG_ERR("clock %u: %d", (unsigned)i, ret);
			return ret;
		}
	}
	ret = pinctrl_apply_state(PINCTRL_DT_DEV_CONFIG_GET(ETH_NODE), PINCTRL_STATE_DEFAULT);
	if (ret) {
		LOG_ERR("pinctrl (mac): %d", ret);
		return ret;
	}
	ret = pinctrl_apply_state(PINCTRL_DT_DEV_CONFIG_GET(MDIO_NODE), PINCTRL_STATE_DEFAULT);
	if (ret) {
		LOG_ERR("pinctrl (mdio): %d", ret);
		return ret;
	}

	heth.Instance = ETH;
	heth.Init.MACAddr = mac_addr;
	heth.Init.MediaInterface = HAL_ETH_RMII_MODE;
	heth.Init.TxDesc = tx_desc;
	heth.Init.RxDesc = rx_desc;
	heth.Init.RxBuffLen = RX_BUF_SIZE;

	if (HAL_ETH_Init(&heth) != HAL_OK) {
		LOG_ERR("HAL_ETH_Init failed (%08x)", HAL_ETH_GetError(&heth));
		return -EIO;
	}

	IRQ_CONNECT(DT_IRQN(ETH_NODE), DT_IRQ(ETH_NODE, priority), eth_isr, NULL, 0);
	irq_enable(DT_IRQN(ETH_NODE));

	ret = phy_init();
	if (ret) {
		return ret;
	}
	LOG_INF("Ethernet ready, MAC %02x:%02x:%02x:%02x:%02x:%02x, waiting for the link", mac[0],
		mac[1], mac[2], mac[3], mac[4], mac[5]);
	return 0;
}

/* ---- data ----------------------------------------------------------------- */

int eth_raw_receive(eth_raw_sink_t sink, k_timeout_t timeout)
{
	void *chain = NULL;
	int n = 0;

	if (!started) {
		k_sleep(timeout);
		return 0;
	}
	(void)k_sem_take(&rx_sem, timeout);

	while (HAL_ETH_ReadData(&heth, &chain) == HAL_OK) {
		struct rx_chunk *c = chain;
		size_t len = 0;

		for (struct rx_chunk *p = c; p != NULL; p = p->next) {
			len += p->len;
		}
		if (c != NULL && c->next == NULL) {
			sys_cache_data_invd_range((void *)rx_buf[c - rx_chunk], c->len);
			sink(rx_buf[c - rx_chunk], c->len);
		} else if (c != NULL) {
			/* longer than a buffer: cannot be one of ours */
			stats.rx_dropped++;
		}
		for (struct rx_chunk *p = c; p != NULL;) {
			struct rx_chunk *nx = p->next;

			p->used = false;
			p = nx;
		}
		stats.rx_frames++;
		stats.rx_bytes += len;
		n++;
		chain = NULL;
	}
	return n;
}

int eth_raw_send(const void *frame, size_t len)
{
	ETH_BufferTypeDef buf = {
		.buffer = tx_buf,
		.len = len,
		.next = NULL,
	};
	ETH_TxPacketConfigTypeDef cfg = {
		.Attributes = ETH_TX_PACKETS_FEATURES_CRCPAD,
		.CRCPadCtrl = ETH_CRC_PAD_INSERT,
		.ChecksumCtrl = ETH_CHECKSUM_DISABLE,
		.Length = len,
		.TxBuffer = &buf,
		.pData = NULL,
	};
	int ret = 0;

	if (!started || len > TX_BUF_SIZE) {
		return -ENETDOWN;
	}
	k_mutex_lock(&tx_mtx, K_FOREVER);
	memcpy(tx_buf, frame, len);
	k_sem_reset(&tx_sem);
	if (HAL_ETH_Transmit_IT(&heth, &cfg) != HAL_OK) {
		stats.tx_errors++;
		ret = -EIO;
	} else if (k_sem_take(&tx_sem, K_MSEC(20)) != 0) {
		stats.tx_errors++;
		ret = -ETIMEDOUT;
	} else {
		stats.tx_frames++;
	}
	(void)HAL_ETH_ReleaseTxPacket(&heth);
	k_mutex_unlock(&tx_mtx);
	return ret;
}

void eth_raw_get_stats(struct eth_raw_stats *st)
{
	stats.rx_no_desc = rx_no_desc;
	*st = stats;
}
```

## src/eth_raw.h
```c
/*
 * Raw Ethernet on the STM32H7S78-DK: the HAL ETH driver and the LAN8742 PHY,
 * frames in and out, nothing above them. The link protocol does not need IP,
 * and the Zephyr network stack would copy every frame twice and schedule it
 * through two threads on the way.
 */
#ifndef ETH_RAW_H_
#define ETH_RAW_H_

#include <stdbool.h>
#include <stddef.h>
#include <stdint.h>

#include <zephyr/kernel.h>

/* a received frame, handed to the sink whole (Ethernet header included) */
typedef void (*eth_raw_sink_t)(const uint8_t *frame, size_t len);

int eth_raw_init(const uint8_t mac[6]);

/* PHY link state; polls the PHY, so call it every few hundred milliseconds */
bool eth_raw_link_poll(void);
bool eth_raw_link_up(void);

/* blocks until the frames the DMA has received are handed to the sink, or
   until the timeout; returns the number of frames */
int eth_raw_receive(eth_raw_sink_t sink, k_timeout_t timeout);

/* copies the frame into a DMA buffer and sends it; blocks until the DMA has
   taken it over */
int eth_raw_send(const void *frame, size_t len);

struct eth_raw_stats {
	uint32_t rx_frames;
	uint32_t rx_bytes;
	uint32_t rx_dropped;
	uint32_t rx_no_desc; /* frames the DMA had no descriptor for */   /* no free DMA buffer */
	uint32_t tx_frames;
	uint32_t tx_errors;
	uint32_t irqs;
};

void eth_raw_get_stats(struct eth_raw_stats *st);

#endif /* ETH_RAW_H_ */
```

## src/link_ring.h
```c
/*
 * A ring of received frames: one producer (the Ethernet receive thread), one
 * consumer (the GPU thread). Entries are a 32 bit length and the payload,
 * padded to a word; a length of 0xffffffff means "wrapped, start over".
 */
#ifndef LINK_RING_H_
#define LINK_RING_H_

#include <stdbool.h>
#include <stddef.h>
#include <stdint.h>
#include <string.h>

#include <zephyr/sys/barrier.h>

struct link_ring {
	uint8_t *buf;
	uint32_t size;
	volatile uint32_t head;  /* producer writes here   */
	volatile uint32_t tail;  /* consumer reads here    */
	uint32_t high_water;
	uint32_t errors;         /* entries that made no sense: the ring was reset */
};

#define LINK_RING_WRAP 0xffffffffu

static inline void link_ring_init(struct link_ring *r, uint8_t *buf, uint32_t size)
{
	r->buf = buf;
	r->size = size;
	r->head = 0;
	r->tail = 0;
	r->high_water = 0;
	r->errors = 0;
}

static inline uint32_t link_ring_used(const struct link_ring *r)
{
	uint32_t h = r->head, t = r->tail;

	return h >= t ? h - t : r->size - t + h;
}

static inline uint32_t link_ring_free(const struct link_ring *r)
{
	return r->size - 1u - link_ring_used(r);
}

/* false when it does not fit: the caller drops the frame (flow control should prevent it) */
static inline bool link_ring_put(struct link_ring *r, const void *data, uint32_t len)
{
	uint32_t need = 4u + ((len + 3u) & ~3u);
	uint32_t h = r->head;
	uint32_t t = r->tail;

	if (h + need > r->size) {
		/* wrap: the marker needs 4 bytes at the end, the entry goes to the start */
		if (t > h || t == 0u) {
			return false; /* the consumer is between here and the end, or at 0 */
		}
		if (need >= t) {
			return false;
		}
		if (h + 4u <= r->size) {
			*(volatile uint32_t *)&r->buf[h] = LINK_RING_WRAP;
		}
		h = 0;
	} else {
		uint32_t free_now = (h >= t) ? (r->size - h + t) : (t - h);

		if (need >= free_now) {
			return false;
		}
	}
	memcpy(&r->buf[h + 4u], data, len);
	*(volatile uint32_t *)&r->buf[h] = len;
	barrier_dmem_fence_full();
	/* an entry that ends exactly at the end: the next one starts at 0, no marker */
	r->head = (h + need == r->size) ? 0u : h + need;
	uint32_t used = link_ring_used(r);

	if (used > r->high_water) {
		r->high_water = used;
	}
	return true;
}

/* the oldest entry, or NULL; the consumer calls link_ring_drop() when done with it */
static inline const uint8_t *link_ring_peek(struct link_ring *r, uint32_t *len)
{
	uint32_t t = r->tail;

	if (t == r->size) {
		/* the last entry ended exactly at the end (see link_ring_put) */
		r->tail = 0;
		t = 0;
	}
	if (t == r->head) {
		return NULL;
	}
	uint32_t l = *(volatile uint32_t *)&r->buf[t];

	if (l == LINK_RING_WRAP) {
		barrier_dmem_fence_full();
		r->tail = 0;
		t = 0;
		if (t == r->head) {
			return NULL;
		}
		l = *(volatile uint32_t *)&r->buf[t];
	}
	if (l > r->size - 8u) {
		/* not a length: the ring is out of step - start over rather than fault */
		barrier_dmem_fence_full();
		r->tail = r->head;
		r->errors++;
		return NULL;
	}
	barrier_dmem_fence_full();
	*len = l;
	return &r->buf[t + 4u];
}

static inline void link_ring_drop(struct link_ring *r, uint32_t len)
{
	barrier_dmem_fence_full();
	r->tail = r->tail + 4u + ((len + 3u) & ~3u);
}

#endif /* LINK_RING_H_ */
```

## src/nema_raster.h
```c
/*
 * The PSX GPU's primitives on the NeoChrom: what gpu.c calls instead of
 * rasterizing them itself (PSX_GPU_EXTERNAL_RASTER). See nema_raster.c.
 */
#ifndef NEMA_RASTER_H_
#define NEMA_RASTER_H_

#include <stdint.h>

#include "gpu.h"

void psx_raster_init(void);

/* how the GPU reads a PSX texture, checked against known data at boot */
void psx_raster_selftest(psx_gpu_t *gpu);

/* GP0 primitives drawn by the NeoChrom and by gpu.c, compared (printed, and in g_tritest) */
void psx_raster_tritest(psx_gpu_t *gpu);

/* everything queued is drawn; the CPU may touch VRAM after this */
void psx_raster_sync(void);

/* the hooks gpu.c calls: 1 when the GPU took the primitive, 0 to rasterize it */
int psx_raster_triangle(psx_gpu_t *gpu, vertex_t v0, vertex_t v1, vertex_t v2, poly_data_t data);
int psx_raster_rect(psx_gpu_t *gpu, rect_data_t data);
int psx_raster_line(psx_gpu_t *gpu, vertex_t v0, vertex_t v1, uint32_t color, int transp);
int psx_raster_fill(psx_gpu_t *gpu, int x, int y, int w, int h, uint32_t color);

struct psx_raster_stats {
	uint32_t prims, flat, gouraud, textured, rects, lines;
	uint32_t tex_binds, palettes, flushes, hangs;
	uint32_t tex15;        /* 15 bit textures, whose red and blue come out swapped */
	uint32_t invalidations; /* times the GPU's read cache had to be dropped */
	uint32_t gpu_cyc;      /* cycles waiting for the GPU to drain the list */
	uint32_t cpu_cyc;      /* ... and building its commands */
	uint32_t bind_cyc;     /* ... of which binding textures and palettes */
};

void psx_raster_get_stats(struct psx_raster_stats *out);
void psx_raster_reset_stats(void);

#endif /* NEMA_RASTER_H_ */
```

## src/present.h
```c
/*
 * From the PSX VRAM to the panel: the display window is repacked to RGB565,
 * the NeoChrom scales it into an 800x480 frame buffer, the LTDC shows it.
 */
#ifndef PRESENT_H_
#define PRESENT_H_

#include <stdbool.h>
#include <stdint.h>

#include "gpu.h"

int present_init(void);

/* the one command list everything on this board draws through */
struct nema_cmdlist_t_;
struct nema_cmdlist_t_ *present_cl(void);

/* a boot-time measurement: how fast the GPU draws PSX sized primitives (needs the VRAM) */
void present_bench(psx_gpu_t *gpu);

/* the vertical blank of the CPU board's GPU timing: show the picture if it changed */
void present_vblank(psx_gpu_t *gpu);

/*
 * The hybrid: the CPU board rasterized the picture and sends it row by row.
 * present_rows() repacks what arrived straight out of the receive buffer - the
 * pixels are never copied anywhere else - and present_show() puts the finished
 * picture on the panel.
 */
void present_rows(const void *px, uint32_t w, uint32_t row, uint32_t rows, uint32_t stride,
		  uint32_t flags);
void present_show(uint32_t w, uint32_t h, uint32_t flags, uint32_t mode);

/* a message instead of the game (the link is not up yet) */
void present_text(const char *line1, const char *line2);

struct present_stats {
	uint32_t frames;        /* presented */
	uint32_t skipped;       /* dirty, but the flip slot was busy */
	uint32_t repack_us;     /* last present: CPU repack   */
	uint32_t gpu_us;        /* last present: GPU scale    */
	uint32_t src_w, src_h;  /* what is being shown */
	uint32_t mode;          /* GP1(08) */
	uint32_t cpu_us_acc;    /* CPU time in presents since the last reset */
	uint32_t repack_acc;    /* cycles repacking the picture being received */
};

void present_get_stats(struct present_stats *st);
void present_stats_reset(void);

#endif /* PRESENT_H_ */
```
